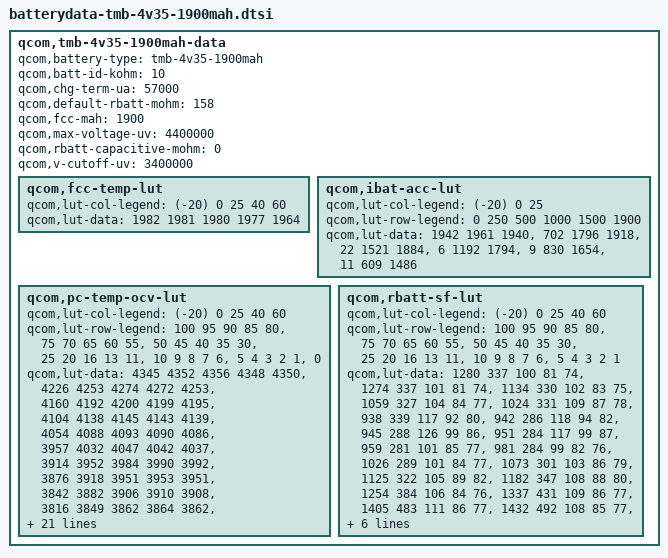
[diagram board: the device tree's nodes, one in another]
/* Copyright (c) 2014, The Linux Foundation. All rights reserved.
 *
 * This program is free software; you can redistribute it and/or modify
 * it under the terms of the GNU General Public License version 2 and
 * only version 2 as published by the Free Software Foundation.
 *
 * This program is distributed in the hope that it will be useful,
 * but WITHOUT ANY WARRANTY; without even the implied warranty of
 * MERCHANTABILITY or FITNESS FOR A PARTICULAR PURPOSE.  See the
 * GNU General Public License for more details.
 */

qcom,tmb-4v35-1900mah-data {
	qcom,battery-type = "tmb-4v35-1900mah";
	qcom,batt-id-kohm = <10>;
	qcom,chg-term-ua = <57000>;
	qcom,default-rbatt-mohm = <158>;
	qcom,fcc-mah = <1900>;
	qcom,max-voltage-uv = <4400000>;
	qcom,rbatt-capacitive-mohm = <0>;
	qcom,v-cutoff-uv = <3400000>;

	qcom,fcc-temp-lut {
		qcom,lut-col-legend = <(-20) 0 25 40 60>;
		qcom,lut-data = <1982 1981 1980 1977 1964>;
	};

	qcom,ibat-acc-lut {
		qcom,lut-col-legend = <(-20) 0 25>;
		qcom,lut-row-legend = <0 250 500 1000 1500 1900>;
		qcom,lut-data = <1942 1961 1940>,
				<702 1796 1918>,
				<22 1521 1884>,
				<6 1192 1794>,
				<9 830 1654>,
				<11 609 1486>;
	};

	qcom,pc-temp-ocv-lut {
		qcom,lut-col-legend = <(-20) 0 25 40 60>;
		qcom,lut-row-legend = <100 95 90 85 80>,
					<75 70 65 60 55>,
					<50 45 40 35 30>,
					<25 20 16 13 11>,
					<10 9 8 7 6>,
					<5 4 3 2 1>,
					<0>;
		qcom,lut-data = <4345 4352 4356 4348 4350>,
				<4226 4253 4274 4272 4253>,
				<4160 4192 4200 4199 4195>,
				<4104 4138 4145 4143 4139>,
				<4054 4088 4093 4090 4086>,
				<3957 4032 4047 4042 4037>,
				<3914 3952 3984 3990 3992>,
				<3876 3918 3951 3953 3951>,
				<3842 3882 3906 3910 3908>,
				<3816 3849 3862 3864 3862>,
				<3798 3822 3832 3832 3832>,
				<3783 3800 3810 3811 3810>,
				<3770 3785 3794 3794 3792>,
				<3758 3774 3778 3780 3778>,
				<3744 3762 3768 3764 3758>,
				<3730 3750 3754 3746 3734>,
				<3713 3731 3738 3730 3715>,
				<3693 3716 3718 3708 3696>,
				<3678 3706 3698 3688 3676>,
				<3662 3699 3690 3682 3670>,
				<3651 3696 3688 3680 3670>,
				<3640 3692 3686 3680 3668>,
				<3627 3687 3684 3678 3666>,
				<3611 3680 3682 3674 3662>,
				<3591 3668 3673 3663 3650>,
				<3568 3645 3646 3632 3618>,
				<3534 3610 3602 3586 3572>,
				<3492 3552 3542 3528 3514>,
				<3429 3477 3459 3449 3436>,
				<3326 3352 3328 3330 3310>,
				<3000 3000 3000 3027 3000>;
	};

	qcom,rbatt-sf-lut {
		qcom,lut-col-legend = <(-20) 0 25 40 60>;
		qcom,lut-row-legend = <100 95 90 85 80>,
					<75 70 65 60 55>,
					<50 45 40 35 30>,
					<25 20 16 13 11>,
					<10 9 8 7 6>,
					<5 4 3 2 1>;
		qcom,lut-data = <1280 337 100 81 74>,
				<1274 337 101 81 74>,
				<1134 330 102 83 75>,
				<1059 327 104 84 77>,
				<1024 331 109 87 78>,
				<938 339 117 92 80>,
				<942 286 118 94 82>,
				<945 288 126 99 86>,
				<951 284 117 99 87>,
				<959 281 101 85 77>,
				<981 284 99 82 76>,
				<1026 289 101 84 77>,
				<1073 301 103 86 79>,
				<1125 322 105 89 82>,
				<1182 347 108 88 80>,
				<1254 384 106 84 76>,
				<1337 431 109 86 77>,
				<1405 483 111 86 77>,
				<1432 492 108 85 77>,
				<1492 540 110 85 77>,
				<1539 572 113 88 78>,
				<1570 610 117 89 80>,
				<1635 653 121 92 81>,
				<1783 700 128 94 82>,
				<2016 754 132 94 82>,
				<2409 809 132 92 80>,
				<2987 877 138 96 82>,
				<3966 972 153 103 85>,
				<5878 1082 177 111 90>,
				<11577 1580 259 125 103>;
	};
};
